# CEC1702 register map
Vendor: Microchip
Registers are 32-bit, read-write, reset 0x0 unless marked. A register's access mark holds for its fields unless they carry their own. Addresses are absolute, and some are shared; only a register's first bit layout is shown; [hi:lo] are bit positions; lines under a group give offsets from that group; {n}, {i} and the like mark numbered series.

## HTM0
0x40009800 PRLD 16-bit
0x40009804 CTRL 16-bit
  [0] CTRL — 1= The Hibernation Timer has a resolution of 0.125s per LSB, which yields a maximum time in excess of 2 hours. 0= The Hibernation Timer has a resolution of 30.5us per LSB, which yields a maximum time of ~2seconds.
0x40009808 CNT 16-bit ro

## HTM1
0x40009820 PRLD 16-bit
0x40009824 CTRL 16-bit
  [0] CTRL — 1= The Hibernation Timer has a resolution of 0.125s per LSB, which yields a maximum time in excess of 2 hours. 0= The Hibernation Timer has a resolution of 30.5us per LSB, which yields a maximum time of ~2seconds.
0x40009828 CNT 16-bit ro

## KMS
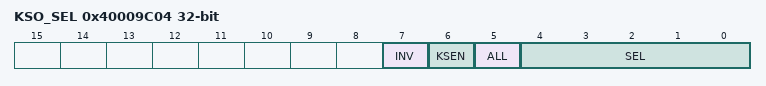
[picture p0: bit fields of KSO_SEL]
0x40009C04 KSO_SEL
  [7] INV — 0= KSO[x] driven low when selected, 1= KSO[x] driven high when selected.
  [6] KSEN — 0= Keyboard scan enabled, 1= Keyboard scan disabled. All KSO output buffers disabled.
  [5] ALL — 0=When key scan is enabled, KSO output controlled by the KSO_SELECT field. 1=KSO[x] driven high when selected.
  [4:0] SEL — This field selects a KSO line (00000b = KSO[0] etc.) for output according to the value off KSO_INVERT in this register.
0x40009C08 KSI ro
0x40009C0C KSI_STS
0x40009C10 KSI_IEN
0x40009C14 EXT_CTRL

## VBAT_RAM
{0x4000A300+4i} MEM_u{i} (i=320..329)
{0x40007600+4i} MEM_u{i} (i=3210..3231)

## ECIA
{0x4000E000+0x14*i} GIRQ{i}SRC (i=0..18)
{0x4000E004+0x14*i} GIRQ{i}EN_SET (i=0..18)
{0x4000E008+0x14*i} GIRQ{i}RESULT ro (i=0..18)
{0x4000E00C+0x14*i} GIRQ{i}EN_CLR (i=0..18)
0x4000E200 BLK_EN_SET
  [30:0] VTOR_EN_SET — Each GIRQx bit can be individually enabled to assert an interrupt event. Reads always return the current value of the internal GIRQX_ENABLE bit. The state of the GIRQX_ENABLE bit is determined by the corresponding GIRQX_ENABLE_SET bit and the GIRQX_ENABLE_ CLEAR bit. (0=disabled, 1=enabled) (R/WS). 1=Interrupts in the GIRQx Source Register may be enabled. 0=No effect.
0x4000E204 BLK_EN_CLR
  [30:0] VTOR_EN_CLR — Each GIRQx bit can be individually disabled to inhibit an interrupt event. Reads always return the current value of the internal GIRQX_ENABLE bit. The state of the GIRQX_ENABLE bit is determined by the corresponding GIRQX_ENABLE_SET bit and the GIRQX_ENABLE_ CLEAR bit. (0=disabled, 1=enabled) (R/WC). 1=All interrupts in the GIRQx Source Register are disabled. 0=No effect.
0x4000E208 BLK_IRQ_VTOR ro
  [24:0] VTOR — Each bit in this field reports the status of the group GIRQ interrupt assertion to the NVIC. If the GIRQx interrupt is disabled as a group, by the Block Enable Clear Register, then the corresponding bit will be '0'b and no interrupt will be asserted.

## EFUSE
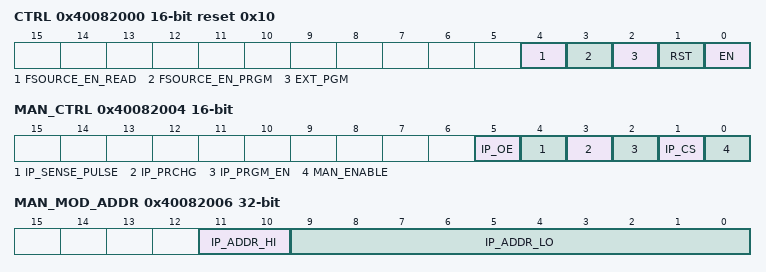
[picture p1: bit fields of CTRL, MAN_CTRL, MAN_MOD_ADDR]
0x40082000 CTRL 16-bit reset 0x10
  [4] FSOURCE_EN_READ — FSOURCE pin enable for reading: 1=FSOURCE switch logic connects eFUSE FSOURCE pin to a power pad for read mode. Only set this bit when FSOURCE_EN_PRGM bit is already 0 to avoid shorting the power pad to ground; 0=FSOURCE switch logic isolates eFUSE FSOURCE pin from ground.
  [3] FSOURCE_EN_PRGM — FSOURCE pin enable for programming: 1=FSOURCE switch logic connects eFUSE FSOURCE pin to a power pad for PROGRAM mode. Only set this bit when FSOURCE_EN_READ bit is already 0 to avoid shorting the power pad to ground; 0=FSOURCE switch logic isolates eFUSE FSOURCE pin from power pad.
  [2] EXT_PGM — External programming enable: 1=eFUSE programming is done via external pin interface 0=Manual/Normal mode. eFUSE programming is done via this block's register set.
  [1] RST — Block reset: 1=Block is reset; 0=Normal operation. This bit self-clears and always reads back 0.
  [0] EN — Block enable: 1=block is enabled for operation; 0=block is disabled and in lowest power state.
0x40082004 MAN_CTRL 16-bit
  [5] IP_OE — eFUSE output enable. The IP might tri-state at various times, so this bit isolates the outputs to avoid potential crowbar. 1=eFUSE outputs enabled for read; 0=eFUSE outputs isolated
  [4] IP_SENSE_PULSE — eFUSE sense, outputs are valid on falling edge of this bit.
  [3] IP_PRCHG — eFUSE precharge: 1=outputs are being precharged; 0=outputs are not precharged.
  [2] IP_PRGM_EN — eFUSE program enable. Can also be considered the write signal: 1=eFUSE is programming; 0=eFUSE is in read mode.
  [1] IP_CS — eFUSE chip select (CS) pin: 1=eFUSE is enabled for PROGRAM/READ modes; 0=eFUSE is disabled and in low power state.
  [0] MAN_ENABLE — Manual mode enable bit: 1=Manual mode is enabled and this register interfaces to the eFUSE; 0=Normal mode, internal controller interfaces to eFUSE IP. This bit only takes affect when REG_CTRL.EXT_PRGM bit is 0.
0x40082006 MAN_MOD_ADDR
  [11:10] IP_ADDR_HI — Manual mode address, selecting a 1K bit block of eFuse data
  [9:0] IP_ADDR_LO — Manual mode address, selecting the bit address within a 1K bit block.
0x4008200C MAN_MOD_DATA
  [15:0] IP_DATA — Manual mode data: This field connects to the eFUSE data output pins.
{0x40082010+4i} EFUSE_MEM_DW{i} (i=0..127)
